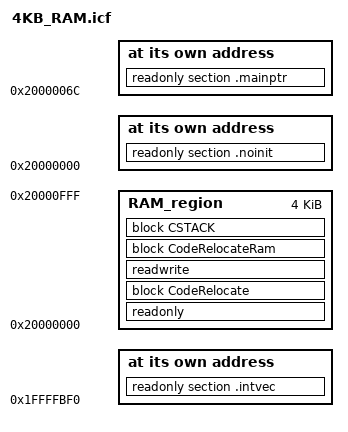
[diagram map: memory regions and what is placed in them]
/*###ICF### Section handled by ICF editor, don't touch! ****/
/*-Editor annotation file-*/
/* IcfEditorFile="$TOOLKIT_DIR$\config\ide\IcfEditor\cortex_v1_0.xml" */
/*-Memory Regions-*/
define symbol __ICFEDIT_region_RAM_end__   = 0x20000fff;
define symbol __ICFEDIT_region_RAM_start__ = 0x20000000;//********
/*-Specials-*/
define symbol __ICFEDIT_intvec_start__     = __ICFEDIT_region_RAM_start__ - 0x410;

/*-Sizes-*/
define symbol __ICFEDIT_size_cstack__ = (1*128);//********
//define symbol __ICFEDIT_size_heap__   = (1*1024);//********
/**** End of ICF editor section. ###ICF###*/


define exported symbol __VECTOR_TABLE      = __ICFEDIT_intvec_start__;
define exported symbol __VECTOR_RAM        = __ICFEDIT_intvec_start__;

define exported symbol __BOOT_STACK_ADDRESS = __ICFEDIT_region_RAM_end__  - 8;

define symbol __code_start__ = __ICFEDIT_region_RAM_start__;//********

define memory mem with size = 4G;
define region RAM_region   = mem:[from __ICFEDIT_region_RAM_start__   to __ICFEDIT_region_RAM_end__ ];

define block CSTACK    with alignment = 8, size = __ICFEDIT_size_cstack__   { };
//define block HEAP      with alignment = 8, size = __ICFEDIT_size_heap__     { };

do not initialize  { readwrite };
initialize manually { section .data};
initialize manually { section .textrw };
do not initialize  { section .noinit };

define block CodeRelocate { section .textrw_init };
define block CodeRelocateRam { section .textrw };
place at address mem:__ICFEDIT_intvec_start__ { readonly section .intvec };
place at address mem:__code_start__ { readonly section .noinit };

place in RAM_region   { readonly, block CodeRelocate};

place in RAM_region   { readwrite, block CodeRelocateRam,
                        block CSTACK };

place at address mem:0x2000006C {readonly section .mainptr};
                      

